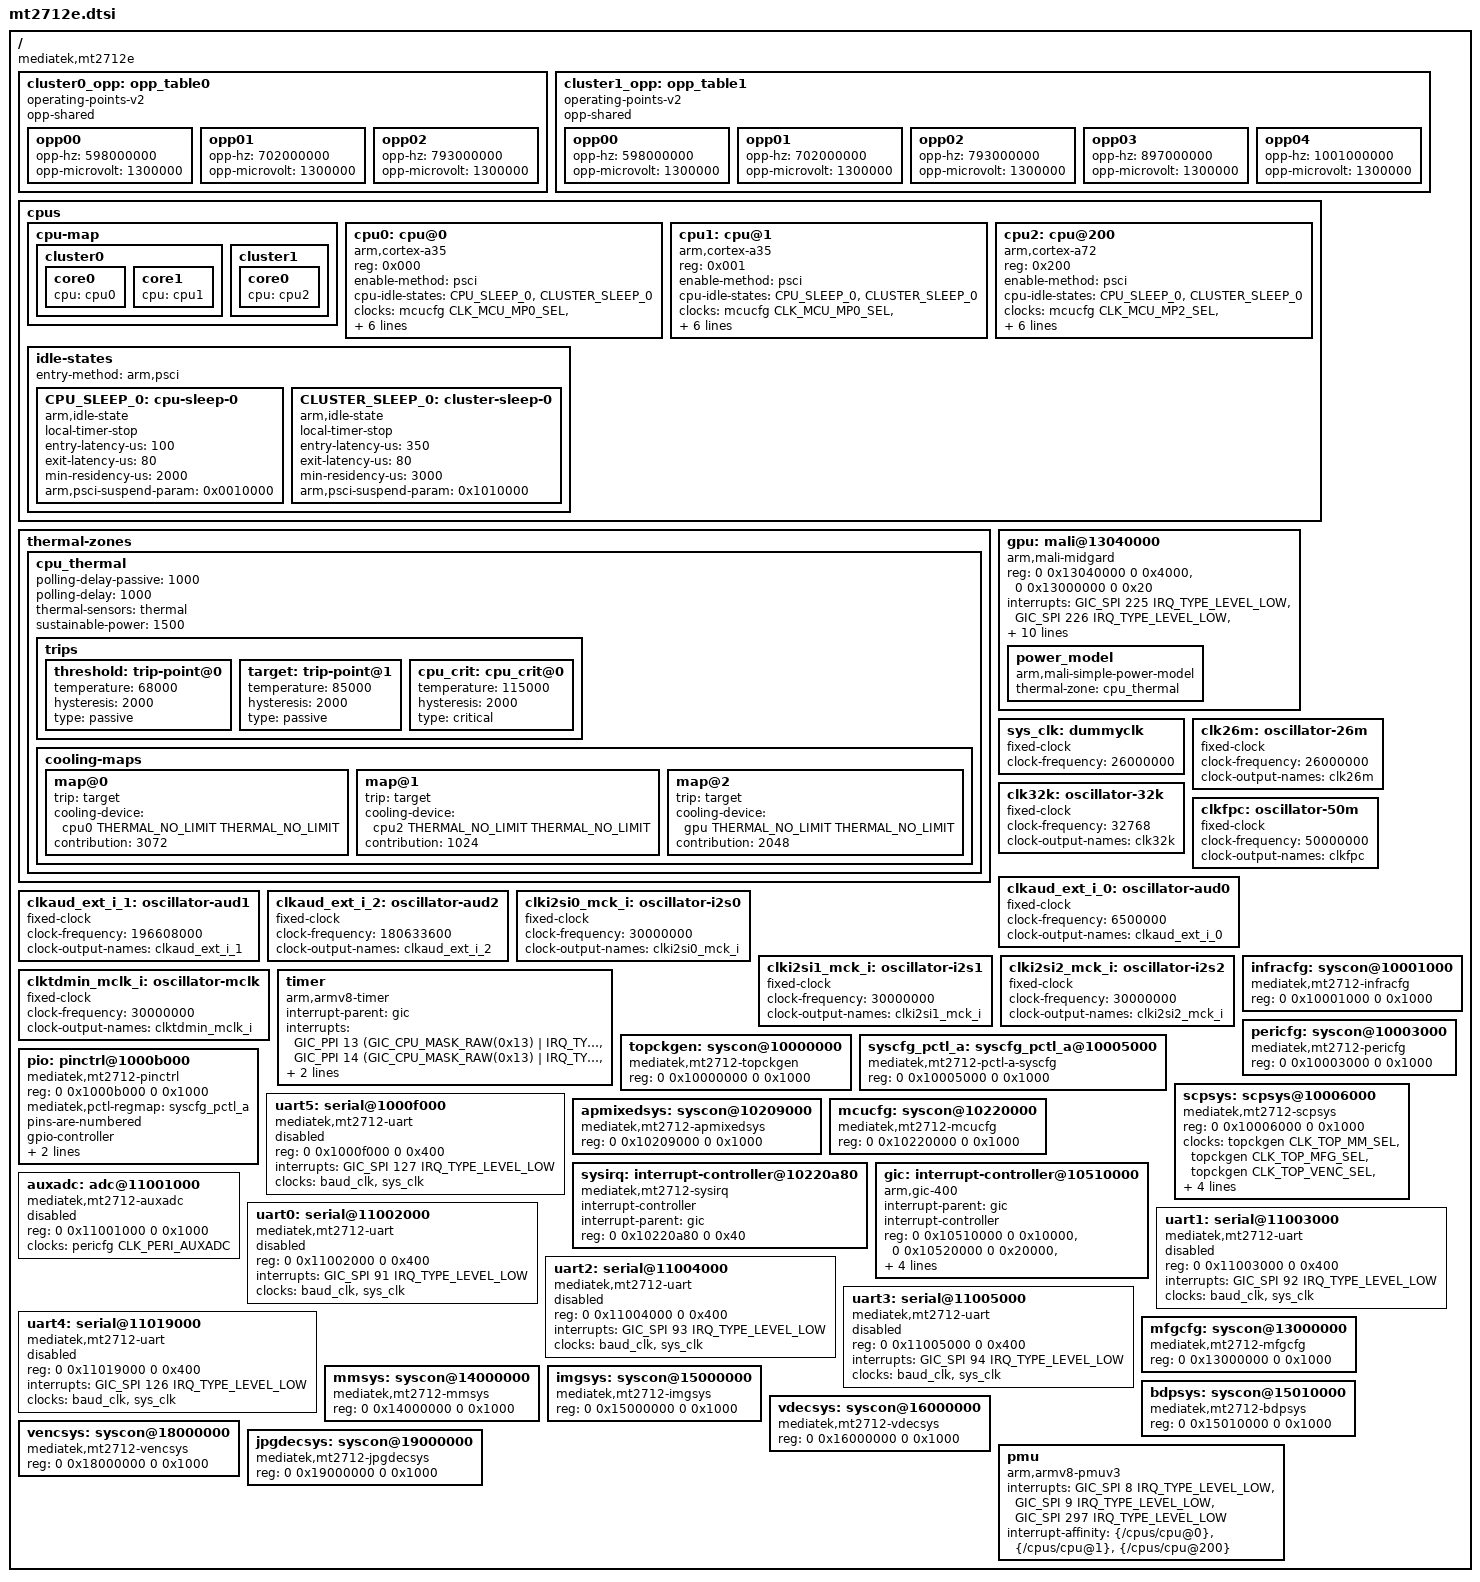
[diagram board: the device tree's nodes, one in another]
// SPDX-License-Identifier: GPL-2.0
/*
 * Copyright (c) 2019 MediaTek Inc.
 */

#include <dt-bindings/thermal/thermal.h>
#include "mt2712.dtsi"

/ {
	compatible = "mediatek,mt2712e";

	cluster0_opp: opp_table0 {
		compatible = "operating-points-v2";
		opp-shared;
		opp00 {
			opp-hz = /bits/ 64 <598000000>;
			opp-microvolt = <1300000>;
		};
		opp01 {
			opp-hz = /bits/ 64 <702000000>;
			opp-microvolt = <1300000>;
		};
		opp02 {
			opp-hz = /bits/ 64 <793000000>;
			opp-microvolt = <1300000>;
		};
	};

	cluster1_opp: opp_table1 {
		compatible = "operating-points-v2";
		opp-shared;
		opp00 {
			opp-hz = /bits/ 64 <598000000>;
			opp-microvolt = <1300000>;
		};
		opp01 {
			opp-hz = /bits/ 64 <702000000>;
			opp-microvolt = <1300000>;
		};
		opp02 {
			opp-hz = /bits/ 64 <793000000>;
			opp-microvolt = <1300000>;
		};
		opp03 {
			opp-hz = /bits/ 64 <897000000>;
			opp-microvolt = <1300000>;
		};
		opp04 {
			opp-hz = /bits/ 64 <1001000000>;
			opp-microvolt = <1300000>;
		};
	};

	cpus {
		#address-cells = <1>;
		#size-cells = <0>;

		cpu-map {
			cluster0 {
				core0 {
					cpu = <&cpu0>;
				};
				core1 {
					cpu = <&cpu1>;
				};
			};

			cluster1 {
				core0 {
					cpu = <&cpu2>;
				};
			};
		};

		cpu0: cpu@0 {
			device_type = "cpu";
			compatible = "arm,cortex-a35";
			reg = <0x000>;
			enable-method = "psci";
			cpu-idle-states = <&CPU_SLEEP_0 &CLUSTER_SLEEP_0>;
			clocks = <&mcucfg CLK_MCU_MP0_SEL>,
				 <&topckgen CLK_TOP_ARMCA35PLL>,
				 <&topckgen CLK_TOP_F_MP0_PLL1>,
				 <&clk26m>;
			clock-names = "cpu", "armpll", "intermediate", "ref_ck";
			operating-points-v2 = <&cluster0_opp>;
			#cooling-cells = <2>;
			dynamic-power-coefficient = <222>;
			sched-energy-costs = <&MT2712E_CPU_COST_0
					      &MT2712E_CLUSTER_COST_0>;
		};

		cpu1: cpu@1 {
			device_type = "cpu";
			compatible = "arm,cortex-a35";
			reg = <0x001>;
			enable-method = "psci";
			cpu-idle-states = <&CPU_SLEEP_0 &CLUSTER_SLEEP_0>;
			clocks = <&mcucfg CLK_MCU_MP0_SEL>,
				 <&topckgen CLK_TOP_ARMCA35PLL>,
				 <&topckgen CLK_TOP_F_MP0_PLL1>,
				 <&clk26m>;
			clock-names = "cpu", "armpll", "intermediate", "ref_ck";
			operating-points-v2 = <&cluster0_opp>;
			dynamic-power-coefficient = <222>;
			sched-energy-costs = <&MT2712E_CPU_COST_0
					      &MT2712E_CLUSTER_COST_0>;
		};

		cpu2: cpu@200 {
			device_type = "cpu";
			compatible = "arm,cortex-a72";
			reg = <0x200>;
			enable-method = "psci";
			cpu-idle-states = <&CPU_SLEEP_0 &CLUSTER_SLEEP_0>;
			clocks = <&mcucfg CLK_MCU_MP2_SEL>,
				 <&topckgen CLK_TOP_ARMCA72PLL>,
				 <&topckgen CLK_TOP_F_BIG_PLL1>,
				 <&clk26m>;
			clock-names = "cpu", "armpll", "intermediate", "ref_ck";
			operating-points-v2 = <&cluster1_opp>;
			#cooling-cells = <2>;
			dynamic-power-coefficient = <475>;
			sched-energy-costs = <&MT2712E_CPU_COST_1
					      &MT2712E_CLUSTER_COST_1>;
		};

		/include/ "mt2712-sched-energy.dtsi"

		idle-states {
			entry-method = "arm,psci";

			CPU_SLEEP_0: cpu-sleep-0 {
				compatible = "arm,idle-state";
				local-timer-stop;
				entry-latency-us = <100>;
				exit-latency-us = <80>;
				min-residency-us = <2000>;
				arm,psci-suspend-param = <0x0010000>;
			};

			CLUSTER_SLEEP_0: cluster-sleep-0 {
				compatible = "arm,idle-state";
				local-timer-stop;
				entry-latency-us = <350>;
				exit-latency-us = <80>;
				min-residency-us = <3000>;
				arm,psci-suspend-param = <0x1010000>;
			};
		};
	};

	thermal-zones {
		cpu_thermal: cpu_thermal {
			polling-delay-passive = <1000>; /* milliseconds */
			polling-delay = <1000>; /* milliseconds */
			thermal-sensors = <&thermal>;
			sustainable-power = <1500>; /* milliwatts */

			trips {
				threshold: trip-point@0 {
					temperature = <68000>;
					hysteresis = <2000>;
					type = "passive";
				};

				target: trip-point@1 {
					temperature = <85000>;
					hysteresis = <2000>;
					type = "passive";
				};

				cpu_crit: cpu_crit@0 {
					temperature = <115000>;
					hysteresis = <2000>;
					type = "critical";
				};
			};

			cooling-maps {
				map@0 {
					trip = <&target>;
					cooling-device = <&cpu0 THERMAL_NO_LIMIT THERMAL_NO_LIMIT>;
					contribution = <3072>;
				};
				map@1 {
					trip = <&target>;
					cooling-device = <&cpu2 THERMAL_NO_LIMIT THERMAL_NO_LIMIT>;
					contribution = <1024>;
				};
				map@2 {
					trip = <&target>;
					cooling-device = <&gpu THERMAL_NO_LIMIT THERMAL_NO_LIMIT>;
					contribution = <2048>;
				};
			};
		};
	};

	gpu: mali@13040000 {
		compatible = "arm,mali-midgard";
		reg = <0 0x13040000 0 0x4000>, <0 0x13000000 0 0x20>;
		interrupts = <GIC_SPI 225 IRQ_TYPE_LEVEL_LOW>,
			     <GIC_SPI 226 IRQ_TYPE_LEVEL_LOW>,
			     <GIC_SPI 227 IRQ_TYPE_LEVEL_LOW>;
		interrupt-names = "GPU", "MMU", "JOB";
		clocks = <&topckgen CLK_TOP_MFG_SEL>,
			 <&topckgen CLK_TOP_MMPLL>,
			 <&mfgcfg CLK_MFG_BG3D>;
		clock-names = "mfg_sel", "mfg_pll", "mfg_bg3d";
		power-domains = <&scpsys MT2712_POWER_DOMAIN_MFG_SC1>;
		mp=<2>;
		#cooling-cells = <2>;
		#cooling-min-level = <0>;
		#cooling-max-level = <5>;
		operating-points = <
			520000 1000000
			494000 1000000
			455000 1000000
			396500 1000000
			299000 1000000
			253500 1000000
		>;

		power_model {
			compatible = "arm,mali-simple-power-model";
			thermal-zone = "cpu_thermal";
		};
	};

	sys_clk: dummyclk {
		compatible = "fixed-clock";
		clock-frequency = <26000000>;
		#clock-cells = <0>;
	};

	clk26m: oscillator-26m {
		compatible = "fixed-clock";
		#clock-cells = <0>;
		clock-frequency = <26000000>;
		clock-output-names = "clk26m";
	};

	clk32k: oscillator-32k {
		compatible = "fixed-clock";
		#clock-cells = <0>;
		clock-frequency = <32768>;
		clock-output-names = "clk32k";
	};

	clkfpc: oscillator-50m {
		compatible = "fixed-clock";
		#clock-cells = <0>;
		clock-frequency = <50000000>;
		clock-output-names = "clkfpc";
	};

	clkaud_ext_i_0: oscillator-aud0 {
		compatible = "fixed-clock";
		#clock-cells = <0>;
		clock-frequency = <6500000>;
		clock-output-names = "clkaud_ext_i_0";
	};

	clkaud_ext_i_1: oscillator-aud1 {
		compatible = "fixed-clock";
		#clock-cells = <0>;
		clock-frequency = <196608000>;
		clock-output-names = "clkaud_ext_i_1";
	};

	clkaud_ext_i_2: oscillator-aud2 {
		compatible = "fixed-clock";
		#clock-cells = <0>;
		clock-frequency = <180633600>;
		clock-output-names = "clkaud_ext_i_2";
	};

	clki2si0_mck_i: oscillator-i2s0 {
		compatible = "fixed-clock";
		#clock-cells = <0>;
		clock-frequency = <30000000>;
		clock-output-names = "clki2si0_mck_i";
	};

	clki2si1_mck_i: oscillator-i2s1 {
		compatible = "fixed-clock";
		#clock-cells = <0>;
		clock-frequency = <30000000>;
		clock-output-names = "clki2si1_mck_i";
	};

	clki2si2_mck_i: oscillator-i2s2 {
		compatible = "fixed-clock";
		#clock-cells = <0>;
		clock-frequency = <30000000>;
		clock-output-names = "clki2si2_mck_i";
	};

	clktdmin_mclk_i: oscillator-mclk {
		compatible = "fixed-clock";
		#clock-cells = <0>;
		clock-frequency = <30000000>;
		clock-output-names = "clktdmin_mclk_i";
	};

	timer {
		compatible = "arm,armv8-timer";
		interrupt-parent = <&gic>;
		interrupts = <GIC_PPI 13
			      (GIC_CPU_MASK_RAW(0x13) | IRQ_TYPE_LEVEL_LOW)>,
			     <GIC_PPI 14
			      (GIC_CPU_MASK_RAW(0x13) | IRQ_TYPE_LEVEL_LOW)>,
			     <GIC_PPI 11
			      (GIC_CPU_MASK_RAW(0x13) | IRQ_TYPE_LEVEL_LOW)>,
			     <GIC_PPI 10
			      (GIC_CPU_MASK_RAW(0x13) | IRQ_TYPE_LEVEL_LOW)>;
	};

	topckgen: syscon@10000000 {
		compatible = "mediatek,mt2712-topckgen", "syscon";
		reg = <0 0x10000000 0 0x1000>;
		#clock-cells = <1>;
	};

	infracfg: syscon@10001000 {
		compatible = "mediatek,mt2712-infracfg", "syscon";
		reg = <0 0x10001000 0 0x1000>;
		#clock-cells = <1>;
	};

	pericfg: syscon@10003000 {
		compatible = "mediatek,mt2712-pericfg", "syscon";
		reg = <0 0x10003000 0 0x1000>;
		#clock-cells = <1>;
	};

	syscfg_pctl_a: syscfg_pctl_a@10005000 {
		compatible = "mediatek,mt2712-pctl-a-syscfg", "syscon";
		reg = <0 0x10005000 0 0x1000>;
	};

	pio: pinctrl@1000b000 {
		compatible = "mediatek,mt2712-pinctrl";
		reg = <0 0x1000b000 0 0x1000>;
		mediatek,pctl-regmap = <&syscfg_pctl_a>;
		pins-are-numbered;
		gpio-controller;
		#gpio-cells = <2>;
		interrupt-controller;
		#interrupt-cells = <2>;
		interrupts = <GIC_SPI 153 IRQ_TYPE_LEVEL_HIGH>;
	};

	scpsys: scpsys@10006000 {
		compatible = "mediatek,mt2712-scpsys", "syscon";
		#power-domain-cells = <1>;
		reg = <0 0x10006000 0 0x1000>;
		clocks = <&topckgen CLK_TOP_MM_SEL>,
			 <&topckgen CLK_TOP_MFG_SEL>,
			 <&topckgen CLK_TOP_VENC_SEL>,
			 <&topckgen CLK_TOP_JPGDEC_SEL>,
			 <&topckgen CLK_TOP_A1SYS_HP_SEL>,
			 <&topckgen CLK_TOP_VDEC_SEL>;
		clock-names = "mm", "mfg", "venc",
			"jpgdec", "audio", "vdec";
		infracfg = <&infracfg>;
	};

	uart5: serial@1000f000 {
		compatible = "mediatek,mt2712-uart",
			     "mediatek,mt6577-uart";
		reg = <0 0x1000f000 0 0x400>;
		interrupts = <GIC_SPI 127 IRQ_TYPE_LEVEL_LOW>;
		clocks = <&baud_clk>, <&sys_clk>;
		clock-names = "baud", "bus";
		status = "disabled";
	};

	apmixedsys: syscon@10209000 {
		compatible = "mediatek,mt2712-apmixedsys", "syscon";
		reg = <0 0x10209000 0 0x1000>;
		#clock-cells = <1>;
	};

	mcucfg: syscon@10220000 {
		compatible = "mediatek,mt2712-mcucfg", "syscon";
		reg = <0 0x10220000 0 0x1000>;
		#clock-cells = <1>;
	};

	sysirq: interrupt-controller@10220a80 {
		compatible = "mediatek,mt2712-sysirq",
			     "mediatek,mt6577-sysirq";
		interrupt-controller;
		#interrupt-cells = <3>;
		interrupt-parent = <&gic>;
		reg = <0 0x10220a80 0 0x40>;
	};

	gic: interrupt-controller@10510000 {
		compatible = "arm,gic-400";
		#interrupt-cells = <3>;
		interrupt-parent = <&gic>;
		interrupt-controller;
		reg = <0 0x10510000 0 0x10000>,
		      <0 0x10520000 0 0x20000>,
		      <0 0x10540000 0 0x20000>,
		      <0 0x10560000 0 0x20000>;
		interrupts = <GIC_PPI 9
			 (GIC_CPU_MASK_RAW(0x13) | IRQ_TYPE_LEVEL_HIGH)>;
	};

	auxadc: adc@11001000 {
		compatible = "mediatek,mt2712-auxadc";
		reg = <0 0x11001000 0 0x1000>;
		clocks = <&pericfg CLK_PERI_AUXADC>;
		clock-names = "main";
		#io-channel-cells = <1>;
		status = "disabled";
	};

	uart0: serial@11002000 {
		compatible = "mediatek,mt2712-uart",
			     "mediatek,mt6577-uart";
		reg = <0 0x11002000 0 0x400>;
		interrupts = <GIC_SPI 91 IRQ_TYPE_LEVEL_LOW>;
		clocks = <&baud_clk>, <&sys_clk>;
		clock-names = "baud", "bus";
		status = "disabled";
	};

	uart1: serial@11003000 {
		compatible = "mediatek,mt2712-uart",
			     "mediatek,mt6577-uart";
		reg = <0 0x11003000 0 0x400>;
		interrupts = <GIC_SPI 92 IRQ_TYPE_LEVEL_LOW>;
		clocks = <&baud_clk>, <&sys_clk>;
		clock-names = "baud", "bus";
		status = "disabled";
	};

	uart2: serial@11004000 {
		compatible = "mediatek,mt2712-uart",
			     "mediatek,mt6577-uart";
		reg = <0 0x11004000 0 0x400>;
		interrupts = <GIC_SPI 93 IRQ_TYPE_LEVEL_LOW>;
		clocks = <&baud_clk>, <&sys_clk>;
		clock-names = "baud", "bus";
		status = "disabled";
	};

	uart3: serial@11005000 {
		compatible = "mediatek,mt2712-uart",
			     "mediatek,mt6577-uart";
		reg = <0 0x11005000 0 0x400>;
		interrupts = <GIC_SPI 94 IRQ_TYPE_LEVEL_LOW>;
		clocks = <&baud_clk>, <&sys_clk>;
		clock-names = "baud", "bus";
		status = "disabled";
	};

	uart4: serial@11019000 {
		compatible = "mediatek,mt2712-uart",
			     "mediatek,mt6577-uart";
		reg = <0 0x11019000 0 0x400>;
		interrupts = <GIC_SPI 126 IRQ_TYPE_LEVEL_LOW>;
		clocks = <&baud_clk>, <&sys_clk>;
		clock-names = "baud", "bus";
		status = "disabled";
	};

	mfgcfg: syscon@13000000 {
		compatible = "mediatek,mt2712-mfgcfg", "syscon";
		reg = <0 0x13000000 0 0x1000>;
		#clock-cells = <1>;
	};

	mmsys: syscon@14000000 {
		compatible = "mediatek,mt2712-mmsys", "syscon";
		reg = <0 0x14000000 0 0x1000>;
		#clock-cells = <1>;
	};

	imgsys: syscon@15000000 {
		compatible = "mediatek,mt2712-imgsys", "syscon";
		reg = <0 0x15000000 0 0x1000>;
		#clock-cells = <1>;
	};

	bdpsys: syscon@15010000 {
		compatible = "mediatek,mt2712-bdpsys", "syscon";
		reg = <0 0x15010000 0 0x1000>;
		#clock-cells = <1>;
	};

	vdecsys: syscon@16000000 {
		compatible = "mediatek,mt2712-vdecsys", "syscon";
		reg = <0 0x16000000 0 0x1000>;
		#clock-cells = <1>;
	};

	vencsys: syscon@18000000 {
		compatible = "mediatek,mt2712-vencsys", "syscon";
		reg = <0 0x18000000 0 0x1000>;
		#clock-cells = <1>;
	};

	jpgdecsys: syscon@19000000 {
		compatible = "mediatek,mt2712-jpgdecsys", "syscon";
		reg = <0 0x19000000 0 0x1000>;
		#clock-cells = <1>;
	};

	pmu {
		compatible = "arm,armv8-pmuv3";
		interrupts = <GIC_SPI 8 IRQ_TYPE_LEVEL_LOW>,
			     <GIC_SPI 9 IRQ_TYPE_LEVEL_LOW>,
			     <GIC_SPI 297 IRQ_TYPE_LEVEL_LOW>;
		interrupt-affinity = <&{/cpus/cpu@0}>,
				     <&{/cpus/cpu@1}>,
				     <&{/cpus/cpu@200}>;
	};
};
